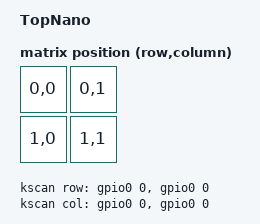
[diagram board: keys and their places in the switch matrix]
// This file was generated from a template. Edit it to match your keyboard.
// See https://docs.zephyrproject.org/3.5.0/hardware/porting/board_porting.html
// and https://zmk.dev/docs/development/hardware-integration/new-shield for more
// instructions.

/dts-v1/;
#include <nordic/nrf52840_qiaa.dtsi>
#include <dt-bindings/zmk/matrix_transform.h>

#include "topnano-pinctrl.dtsi"
#include "topnano-layouts.dtsi"

/ {
    model = "TopNano";
    compatible = "topnano";

    chosen {
        zephyr,code-partition = &code_partition;
        zephyr,console = &cdc_acm_uart;
        zephyr,sram = &sram0;
        zephyr,flash = &flash0;
        // Uncomment this if you enabled one of the "vddh" nodes below.
        // zmk,battery = &vbatt;
        zmk,physical-layout = &default_layout;
    };

    kscan: kscan {
        // If the hardware does not use a switch matrix, change this to the
        // appropriate driver and update the properties below to match.
        // See https://zmk.dev/docs/config/kscan for supported key scan drivers.
        compatible = "zmk,kscan-gpio-matrix";
        // Set this to "col2row" or "row2col" to match the hardware. If using
        // "row2col", change the col-gpios to (GPIO_ACTIVE_HIGH | GPIO_PULL_DOWN)
        // and the row-gpios to GPIO_ACTIVE_HIGH.
        diode-direction = "col2row";
        wakeup-source;

        // Replace these comments with the GPIO pins in the matrix.
        // See https://zmk.dev/docs/development/hardware-integration/new-shield#shield-overlays
        col-gpios
            = <&gpio0 0 GPIO_ACTIVE_HIGH>
            , <&gpio0 0 GPIO_ACTIVE_HIGH>
            ;

        row-gpios
            = <&gpio0 0 (GPIO_ACTIVE_HIGH | GPIO_PULL_DOWN)>
            , <&gpio0 0 (GPIO_ACTIVE_HIGH | GPIO_PULL_DOWN)>
            ;
    };

    default_transform: default_transform {
        // See https://zmk.dev/docs/development/hardware-integration/new-shield#matrix-transform
        // for how to configure this
        compatible = "zmk,matrix-transform";
        columns = <2>;
        rows = <2>;

        map = <
            RC(0, 0) RC(0, 1)
            RC(1, 0) RC(1, 1)
        >;
    };

    leds {
        compatible = "gpio-leds";

        // If you have a GPIO routed to a status LED, set it here.
        // Otherwise, delete this block.
        blue_led: led_0 {
            gpios = <&gpio0 0 GPIO_ACTIVE_HIGH>;
        };
    };

    // If you are powering the SoC from the VDDH pin, uncomment this block.
    // Otherwise, delete it.

    // vbatt: vbatt {
    //     compatible = "zmk,battery-nrf-vddh";
    // };

    // If you are powering the SoC from the VDD pin and you have a voltage divider
    // routed to an analog pin to read the battery voltage, uncomment this block
    // and assign the correct ADC channel and resistance values.
    // Otherwise, delete it.

    // vbatt: vbatt {
    //     compatible = "voltage-divider";
    //     io-channels = <&adc 2>;
    //     output-ohms = <2000000>;
    //     full-ohms = <(2000000 + 806000)>;
    // };
};

&adc {
    status = "okay";
};

&gpiote {
    status = "okay";
};

&gpio0 {
    status = "okay";
};

&gpio1 {
    status = "okay";
};

&uart0 {
    compatible = "nordic,nrf-uarte";
    current-speed = <115200>;
    pinctrl-0 = <&uart0_default>;
    pinctrl-1 = <&uart0_sleep>;
    pinctrl-names = "default", "sleep";
};

zephyr_udc0: &usbd {
    status = "okay";
};

&flash0 {
    // Adjust this flash map as is necessary for your board. For more information, see
    // https://docs.zephyrproject.org/3.5.0/services/storage/flash_map/flash_map.html#relationship-with-devicetree
    partitions {
        compatible = "fixed-partitions";
        #address-cells = <1>;
        #size-cells = <1>;

        code_partition: partition@1000 {
            reg = <DT_SIZE_K(4) DT_SIZE_K(844)>;
        };

        // If using a bootloader with SoftDevice included, replace the code_partition
        // node above with the following. If using SoftDevice v7, change 26000 to 27000.

        // sd_partition: partition@0 {
        //     reg = <0x0 <DT_SIZE_K(4)>;
        // };
        // code_partition: partition@26000 {
        //     reg = <DT_SIZE_K(152) DT_SIZE_K(792)>;
        // };

        // The flash starting at 0x000d4000 and ending at
        // 0x000f3fff is reserved for use by the application.

        // Storage partition will be used by NVS if enabled.
        storage_partition: partition@d4000 {
            reg = <DT_SIZE_K(848) DT_SIZE_K(128)>;
        };

        boot_partition: partition@f4000 {
            reg = <DT_SIZE_K(976) DT_SIZE_K(48)>;
        };
    };
};
